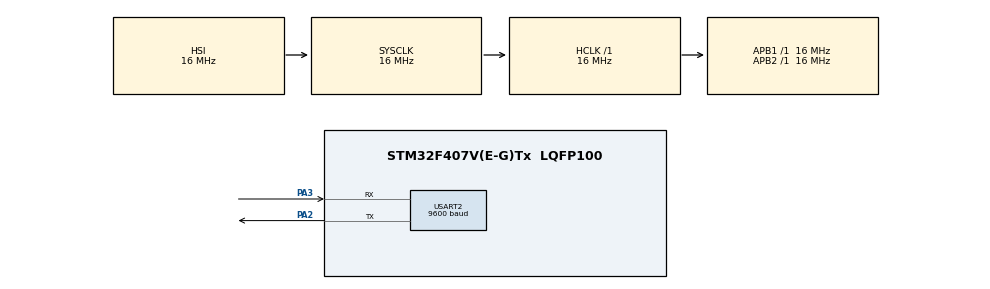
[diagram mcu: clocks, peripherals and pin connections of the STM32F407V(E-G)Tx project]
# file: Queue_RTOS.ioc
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Mcu.Family=STM32F4
FREERTOS.Queues01=SimpleQ,16,uint16_t,0,Dynamic,NULL,NULL
VP_SYS_VS_tim6.Mode=TIM6
RCC.CortexFreq_Value=16000000
FREERTOS.Tasks01=Sender_HPT,2,128,StartSender_HPT,Default,NULL,Dynamic,NULL,NULL;Sender_LPT,-2,128,StartSender_LPT,Default,NULL,Dynamic,NULL,NULL;Receiver,0,128,StartReceiver,Default,NULL,Dynamic,NULL,NULL
NVIC.TIM6_DAC_IRQn=true\:0\:0\:false\:false\:true\:false\:false\:true
USART2.BaudRate=9600
ProjectManager.StackSize=0x400
PA3.Mode=Asynchronous
ProjectManager.TargetToolchain=STM32CubeIDE
RCC.LSE_VALUE=32768
RCC.AHBFreq_Value=16000000
RCC.HSE_VALUE=25000000
board=custom
RCC.VCOOutputFreq_Value=192000000
RCC.APB2Freq_Value=16000000
VP_FREERTOS_VS_CMSIS_V1.Mode=CMSIS_V1
Mcu.Name=STM32F407V(E-G)Tx
PA2.Signal=USART2_TX
RCC.SYSCLKFreq_VALUE=16000000
Mcu.Package=LQFP100
NVIC.TimeBase=TIM6_DAC_IRQn
USART2.VirtualMode=VM_ASYNC
NVIC.TimeBaseIP=TIM6
ProjectManager.HeapSize=0x200
RCC.HSI_VALUE=16000000
NVIC.PriorityGroup=NVIC_PRIORITYGROUP_4
PA2.Mode=Asynchronous
RCC.APB1Freq_Value=16000000
PA3.Signal=USART2_RX

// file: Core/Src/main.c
/* USER CODE BEGIN Header */
/**
  ******************************************************************************
  * @file           : main.c
  * @brief          : Main program body
  ******************************************************************************
  * @attention
  *
  * <h2><center>&copy; Copyright (c) 2021 STMicroelectronics.
  * All rights reserved.</center></h2>
  *
  * This software component is licensed by ST under BSD 3-Clause license,
  * the "License"; You may not use this file except in compliance with the
  * License. You may obtain a copy of the License at:
  *                        opensource.org/licenses/BSD-3-Clause
  *
  ******************************************************************************
  */
/* USER CODE END Header */
#include "main.h"
#include "cmsis_os.h"
#include "usart.h"
#include "gpio.h"

void SystemClock_Config(void);
void MX_FREERTOS_Init(void);

int main(void)
{

  /* MCU Configuration--------------------------------------------------------*/

  /* Reset of all peripherals, Initializes the Flash interface and the Systick. */
  HAL_Init();

  /* Configure the system clock */
  SystemClock_Config();

  /* Initialize all configured peripherals */
  MX_GPIO_Init();
  MX_USART2_UART_Init();

  /* Call init function for freertos objects (in freertos.c) */
  MX_FREERTOS_Init();
  /* Start scheduler */
  osKernelStart();

  /* We should never get here as control is now taken by the scheduler */
  /* Infinite loop */
  while (1)
  {

  }
}

void SystemClock_Config(void)
{
  RCC_OscInitTypeDef RCC_OscInitStruct = {0};
  RCC_ClkInitTypeDef RCC_ClkInitStruct = {0};

  /** Configure the main internal regulator output voltage
  */
  __HAL_RCC_PWR_CLK_ENABLE();
  __HAL_PWR_VOLTAGESCALING_CONFIG(PWR_REGULATOR_VOLTAGE_SCALE1);
  /** Initializes the RCC Oscillators according to the specified parameters
  * in the RCC_OscInitTypeDef structure.
  */
  RCC_OscInitStruct.OscillatorType = RCC_OSCILLATORTYPE_HSI;
  RCC_OscInitStruct.HSIState = RCC_HSI_ON;
  RCC_OscInitStruct.HSICalibrationValue = RCC_HSICALIBRATION_DEFAULT;
  RCC_OscInitStruct.PLL.PLLState = RCC_PLL_NONE;
  if (HAL_RCC_OscConfig(&RCC_OscInitStruct) != HAL_OK)
  {
    Error_Handler();
  }
  /** Initializes the CPU, AHB and APB buses clocks
  */
  RCC_ClkInitStruct.ClockType = RCC_CLOCKTYPE_HCLK|RCC_CLOCKTYPE_SYSCLK
                              |RCC_CLOCKTYPE_PCLK1|RCC_CLOCKTYPE_PCLK2;
  RCC_ClkInitStruct.SYSCLKSource = RCC_SYSCLKSOURCE_HSI;
  RCC_ClkInitStruct.AHBCLKDivider = RCC_SYSCLK_DIV1;
  RCC_ClkInitStruct.APB1CLKDivider = RCC_HCLK_DIV1;
  RCC_ClkInitStruct.APB2CLKDivider = RCC_HCLK_DIV1;

  if (HAL_RCC_ClockConfig(&RCC_ClkInitStruct, FLASH_LATENCY_0) != HAL_OK)
  {
    Error_Handler();
  }
}

 /**
  * @brief  Period elapsed callback in non blocking mode
  * @note   This function is called  when TIM6 interrupt took place, inside
  * HAL_TIM_IRQHandler(). It makes a direct call to HAL_IncTick() to increment
  * a global variable "uwTick" used as application time base.
  * @param  htim : TIM handle
  * @retval None
  */
void HAL_TIM_PeriodElapsedCallback(TIM_HandleTypeDef *htim)
{
  if (htim->Instance == TIM6) {
    HAL_IncTick();
  }
}

void Error_Handler(void)
{
  __disable_irq();
  while (1)
  {
  }
}

/************************ (C) COPYRIGHT STMicroelectronics *****END OF FILE****/

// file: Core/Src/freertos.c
/* USER CODE BEGIN Header */
/**
  ******************************************************************************
  * File Name          : freertos.c
  * Description        : Simple example of how Queues works on FreeRTOS
  * In this ex two tasks try to send a number to a third task and the queue should
  * receive both numbers and send them in the right order
  * note that the NormalPriority task have a lower delay time than the HighPriority
  * So, the sequence of numbers should be 222 (HPT output) and two 111 (LPT output)
  ******************************************************************************
  * @attention
  *
  * <h2><center>&copy; Copyright (c) 2021 STMicroelectronics.
  * All rights reserved.</center></h2>
  *
  * This software component is licensed by ST under Ultimate Liberty license
  * SLA0044, the "License"; You may not use this file except in compliance with
  * the License. You may obtain a copy of the License at:
  *                             www.st.com/SLA0044
  *
  ******************************************************************************
  */
/* USER CODE END Header */

#include "FreeRTOS.h"
#include "task.h"
#include "main.h"
#include "cmsis_os.h"

/* USER CODE BEGIN Includes */
#include "usart.h"
#include "string.h"
#include "stdio.h"
/* USER CODE END Includes */

osThreadId Sender_HPTHandle;
osThreadId Sender_LPTHandle;
osThreadId ReceiverHandle;
osMessageQId SimpleQHandle;

void StartSender_HPT(void const * argument);
void StartSender_LPT(void const * argument);
void StartReceiver(void const * argument);

void MX_FREERTOS_Init(void); /* (MISRA C 2004 rule 8.1) */

/* GetIdleTaskMemory prototype (linked to static allocation support) */
void vApplicationGetIdleTaskMemory( StaticTask_t **ppxIdleTaskTCBBuffer, StackType_t **ppxIdleTaskStackBuffer, uint32_t *pulIdleTaskStackSize );

/* USER CODE BEGIN GET_IDLE_TASK_MEMORY */
static StaticTask_t xIdleTaskTCBBuffer;
static StackType_t xIdleStack[configMINIMAL_STACK_SIZE];

void vApplicationGetIdleTaskMemory( StaticTask_t **ppxIdleTaskTCBBuffer, StackType_t **ppxIdleTaskStackBuffer, uint32_t *pulIdleTaskStackSize )
{
  *ppxIdleTaskTCBBuffer = &xIdleTaskTCBBuffer;
  *ppxIdleTaskStackBuffer = &xIdleStack[0];
  *pulIdleTaskStackSize = configMINIMAL_STACK_SIZE;
  /* place for user code */
}
/* USER CODE END GET_IDLE_TASK_MEMORY */

void MX_FREERTOS_Init(void) {

  /* Create the queue(s) */
  /* definition and creation of SimpleQ */
  osMessageQDef(SimpleQ, 16, uint16_t);
  SimpleQHandle = osMessageCreate(osMessageQ(SimpleQ), NULL);

  /* USER CODE BEGIN RTOS_QUEUES */
  /* add queues, ... */
  //Checking if the Queue is working correctly
  if(SimpleQHandle == 0){
	 char*str = "Unable to create Queue\n\n";
	 HAL_UART_Transmit(&huart2, (uint8_t*)str, strlen(str), HAL_MAX_DELAY);
  }
  else{
	  char*str = "Queue Created\n\n";
	  HAL_UART_Transmit(&huart2, (uint8_t*)str, strlen(str), HAL_MAX_DELAY);
  }

  /* USER CODE END RTOS_QUEUES */

  /* Create the thread(s) */
  /* definition and creation of Sender_HPT */
  osThreadDef(Sender_HPT, StartSender_HPT, osPriorityHigh, 0, 128);
  Sender_HPTHandle = osThreadCreate(osThread(Sender_HPT), NULL);

  /* definition and creation of Sender_LPT */
  osThreadDef(Sender_LPT, StartSender_LPT, osPriorityNormal, 0, 128);
  Sender_LPTHandle = osThreadCreate(osThread(Sender_LPT), NULL);

  /* definition and creation of Receiver */
  osThreadDef(Receiver, StartReceiver, osPriorityLow, 0, 128);
  ReceiverHandle = osThreadCreate(osThread(Receiver), NULL);

}

void StartSender_HPT(void const * argument)
{
  /* USER CODE BEGIN StartSender_HPT */
	int i = 222;
	uint32_t TickDelay = pdMS_TO_TICKS(2000);
  /* Infinite loop */
  for(;;)
  {
	  char*str = "Entered SENDER HPT Task\n Sendig a number to the queue\n\n";
	  HAL_UART_Transmit(&huart2, (uint8_t*)str, strlen(str), HAL_MAX_DELAY);

	  if (xQueueSend(SimpleQHandle, &i, portMAX_DELAY) == pdPASS){ //Send the value to the Queue and check if it has been received using the pdPASS mnemonic
		  char*str2 = "Successfully sent the number\n Leaving SENDER HPT\n\n";
		  HAL_UART_Transmit(&huart2, (uint8_t*)str2, strlen(str2), HAL_MAX_DELAY);
	  }
    osDelay(TickDelay);
  }
  /* USER CODE END StartSender_HPT */
}

void StartSender_LPT(void const * argument)
{
  /* USER CODE BEGIN StartSender_LPT */
	int s = 111;
	uint32_t TickDelay = pdMS_TO_TICKS(1000);
  /* Infinite loop */
  for(;;)
  {
	  char*str = "Entered SENDER LPT Task\n Sendig a number to the queue\n\n";
	  HAL_UART_Transmit(&huart2, (uint8_t*)str, strlen(str), HAL_MAX_DELAY);

	 xQueueSend(SimpleQHandle, &s, portMAX_DELAY);

	 char*str2 = "Successfully sent the number\n Leaving SENDER LPT\n\n";
	 HAL_UART_Transmit(&huart2, (uint8_t*)str2, strlen(str2), HAL_MAX_DELAY);

    osDelay(TickDelay);
  }
  /* USER CODE END StartSender_LPT */
}

void StartReceiver(void const * argument)
{
  /* USER CODE BEGIN StartReceiver */
	int received = 0;
	uint32_t TickDelay = pdMS_TO_TICKS(5000);
  /* Infinite loop */
  for(;;)
  {
	  char str[100];
	  strcpy (str, "Entered RECEIVER task\n About to receive a number from the queue\n");
	  HAL_UART_Transmit(&huart2, (uint8_t*)str, strlen(str), HAL_MAX_DELAY);

	  if(xQueueReceive(SimpleQHandle, &received, portMAX_DELAY) != pdTRUE){
		  HAL_UART_Transmit(&huart2, (uint8_t*)"Error in queue", 14, 1000);
	  }
	  else{
		  sprintf(str, "Successfully received the number %d\n Leaving Receiver\n\n", received);
		  HAL_UART_Transmit(&huart2, (uint8_t*)str, strlen(str), HAL_MAX_DELAY);
	  }
    osDelay(TickDelay);
  }
  /* USER CODE END StartReceiver */
}

/************************ (C) COPYRIGHT STMicroelectronics *****END OF FILE****/
